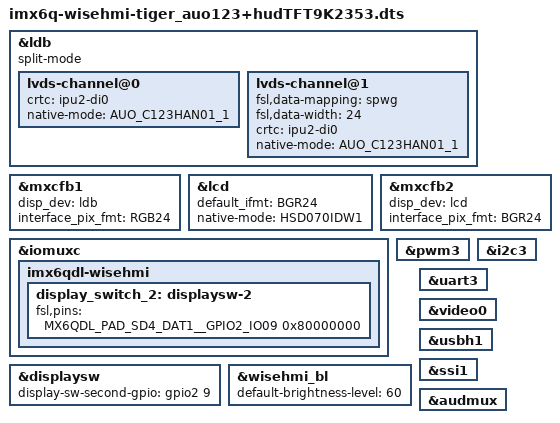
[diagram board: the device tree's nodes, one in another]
#include "imx6q-wisehmi.dts"

&ldb {
	split-mode;

	lvds-channel@0 {
		crtc = "ipu2-di0";
		
		native-mode = <&AUO_C123HAN01_1>;
	};

	lvds-channel@1 {
		fsl,data-mapping = "spwg";
		fsl,data-width = <24>;
		crtc = "ipu2-di0";
		status = "okay";

		native-mode = <&AUO_C123HAN01_1>;
	};
};

&mxcfb1 {
	disp_dev = "ldb";
	interface_pix_fmt = "RGB24";
};

&lcd {
	default_ifmt = "BGR24";
	native-mode = <&HSD070IDW1>;
	status = "okay";
};

&mxcfb2 {
	disp_dev = "lcd";
	interface_pix_fmt = "BGR24";
	status = "okay";
};

&iomuxc {
	imx6qdl-wisehmi {
		display_switch_2: displaysw-2 {
			fsl,pins = <
				MX6QDL_PAD_SD4_DAT1__GPIO2_IO09            0x80000000
			>;
		};
	};
};

&displaysw{
	display-sw-second-gpio = <&gpio2 9 GPIO_ACTIVE_HIGH>;
};

&pwm3 {
	status = "okay";
};

&wisehmi_bl {
	default-brightness-level = <60>; 
	status = "okay";
};

&i2c3 {
	status = "okay";
};

&uart3 {
	status = "okay";
};

&video0{
	status = "okay";
};

&usbh1 {
	status = "okay";
};

&ssi1 {
	status = "okay";
};

&audmux {
	status = "okay";
};

//&gpc {
	/* use ldo-enable, u-boot will check it and configure */
//	fsl,ldo-bypass = <0>;
//};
